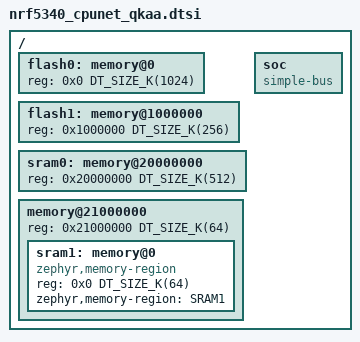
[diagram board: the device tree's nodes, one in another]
/*
 * Copyright (c) 2019 - 2020 Nordic Semiconductor ASA
 *
 * SPDX-License-Identifier: Apache-2.0
 */

#include <mem.h>
#include <nordic/nrf5340_cpunet.dtsi>

/ {
	flash0: memory@0 {
		device_type = "memory";
		reg = <0x0 DT_SIZE_K(1024)>;
		#address-cells = <1>;
		#size-cells = <1>;
		ranges = <0x0 0x10000000 DT_SIZE_K(1024)>;
	};

	flash1: memory@1000000 {
		device_type = "memory";
		reg = <0x1000000 DT_SIZE_K(256)>;
		#address-cells = <1>;
		#size-cells = <1>;
		ranges = <0x0 0x1000000 DT_SIZE_K(256)>;
	};

	sram0: memory@20000000 {
		device_type = "memory";
		reg = <0x20000000 DT_SIZE_K(512)>;
		#address-cells = <1>;
		#size-cells = <1>;
		ranges = <0x0 0x20000000 DT_SIZE_K(512)>;
	};

	memory@21000000 {
		device_type = "memory";
		reg = <0x21000000 DT_SIZE_K(64)>;
		#address-cells = <1>;
		#size-cells = <1>;
		ranges = <0x0 0x21000000 DT_SIZE_K(64)>;

		sram1: memory@0 {
			compatible = "zephyr,memory-region";
			reg = <0x0 DT_SIZE_K(64)>;
			zephyr,memory-region = "SRAM1";
			#address-cells = <1>;
			#size-cells = <1>;
		};
	};

	soc {
		compatible = "simple-bus";
	};
};
